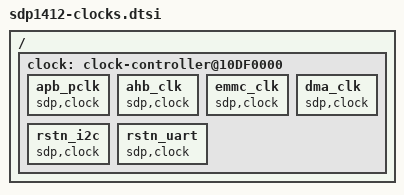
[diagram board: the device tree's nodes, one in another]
/*
 * Copyright (C) 2013 Samsung Electronics Co.Ltd
 *
 * This program is free software; you can redistribute it and/or modify
 * it under the terms of the GNU General Public License version 2 as
 * published by the Free Software Foundation.
 */

/ {
	clock: clock-controller@10DF0000 {
		apb_pclk: apb_pclk {
			sdp,clock;
			#clock-cells = <0>;
		};
		
		ahb_clk: ahb_clk {
			sdp,clock;
			#clock-cells = <0>;
		};
		
		emmc_clk: emmc_clk {
			sdp,clock;
			#clock-cells = <0>;
		};

		dma_clk: dma_clk {
			sdp,clock;
			#clock-cells = <0>;
		};

		rstn_i2c: rstn_i2c {
			sdp,clock;
			#clock-cells = <0>;
		};
		
		rstn_uart: rstn_uart {
			sdp,clock;
			#clock-cells = <0>;
		};
	};
};
